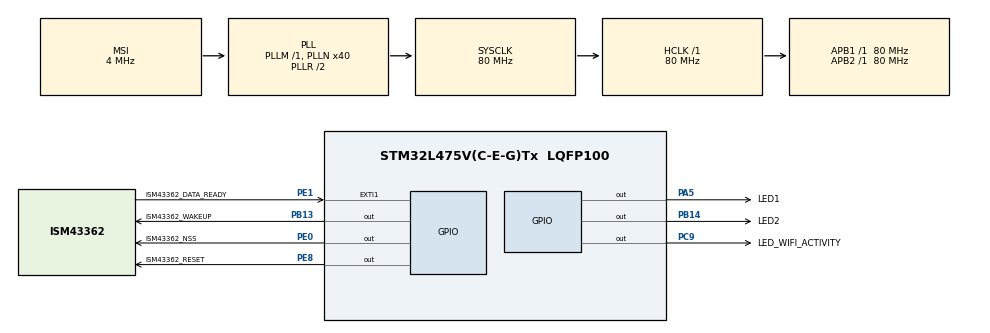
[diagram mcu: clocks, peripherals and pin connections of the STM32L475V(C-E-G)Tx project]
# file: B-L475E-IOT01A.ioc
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Mcu.Family=STM32L4
Mcu.Name=STM32L475V(C-E-G)Tx
Mcu.Package=LQFP100
Mcu.UserConstants=HTS221_I2C,hi2c2
NVIC.EXTI1_IRQn=true\:0\:0\:false\:false\:true\:true\:true
NVIC.PriorityGroup=NVIC_PRIORITYGROUP_4
PA5.GPIO_Label=LED1
PA5.Signal=GPIO_Output
PB13.GPIO_Label=ISM43362_WAKEUP
PB13.Signal=GPIO_Output
PB14.GPIO_Label=LED2
PB14.Signal=GPIO_Output
PB6.Signal=USART1_TX
PB7.Signal=USART1_RX
PC9.GPIO_Label=LED_WIFI_ACTIVITY
PC9.Signal=GPIO_Output
PE0.GPIO_Label=ISM43362_NSS
PE0.PinState=GPIO_PIN_SET
PE0.Signal=GPIO_Output
PE1.GPIO_Label=ISM43362_DATA_READY
PE1.Signal=GPXTI1
PE8.GPIO_Label=ISM43362_RESET
PE8.PinState=GPIO_PIN_SET
PE8.Signal=GPIO_Output
ProjectManager.HeapSize=0x200
ProjectManager.StackSize=0x400
ProjectManager.TargetToolchain=EWARM V8.32
RCC.ADCFreq_Value=48000000
RCC.AHBFreq_Value=80000000
RCC.APB1Freq_Value=80000000
RCC.APB1TimFreq_Value=80000000
RCC.APB2Freq_Value=80000000
RCC.APB2TimFreq_Value=80000000
RCC.CortexFreq_Value=80000000
RCC.HCLKFreq_Value=80000000
RCC.HSE_VALUE=8000000
RCC.HSI_VALUE=16000000
RCC.LSE_VALUE=32768
RCC.MSI_VALUE=4000000
RCC.PLLN=40
RCC.PLLSAI1N=24
RCC.SYSCLKFreq_VALUE=80000000
RCC.SYSCLKSource=RCC_SYSCLKSOURCE_PLLCLK
RCC.USBFreq_Value=48000000
RCC.VCOOutputFreq_Value=160000000
STMicroelectronics.X-CUBE-COMPONENTS.1.4.1.ComponentsCcLEDJjLED=GPIO
STMicroelectronics.X-CUBE-COMPONENTS.1.4.1.HTS221_I2C_HANDLER=HTS221_I2C
VP_STMicroelectronics.X-CUBE-COMPONENTS_VS_LEDJjComponents_1.0.0_1.4.1.Mode=LEDJjComponents
board=custom

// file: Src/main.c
/* USER CODE BEGIN Header */
/**
  ******************************************************************************
  * @file           : main.c
  * @brief          : Main program body
  ******************************************************************************
  * @attention
  *
  * <h2><center>&copy; Copyright (c) 2021 STMicroelectronics.
  * All rights reserved.</center></h2>
  *
  * This software component is licensed by ST under Ultimate Liberty license
  * SLA0044, the "License"; You may not use this file except in compliance with
  * the License. You may obtain a copy of the License at:
  *                             www.st.com/SLA0044
  *
  ******************************************************************************
  */
/* USER CODE END Header */
#include "main.h"

/* USER CODE BEGIN Includes */
#include "led.h"
/* USER CODE END Includes */

void SystemClock_Config(void);
static void MX_GPIO_Init(void);

int main(void)
{

  /* MCU Configuration--------------------------------------------------------*/

  /* Reset of all peripherals, Initializes the Flash interface and the Systick. */
  HAL_Init();

  /* Configure the system clock */
  SystemClock_Config();

  /* Initialize all configured peripherals */
  MX_GPIO_Init();

  /* Infinite loop */
  /* USER CODE BEGIN WHILE */
  while (1)
  {
    BSP_LED_Toggle(LED1);
    BSP_LED_Toggle(LED2);
    HAL_Delay(100);
    /* USER CODE END WHILE */

  }
}

void SystemClock_Config(void)
{
  RCC_OscInitTypeDef RCC_OscInitStruct = {0};
  RCC_ClkInitTypeDef RCC_ClkInitStruct = {0};

  /** Initializes the RCC Oscillators according to the specified parameters
  * in the RCC_OscInitTypeDef structure.
  */
  RCC_OscInitStruct.OscillatorType = RCC_OSCILLATORTYPE_MSI;
  RCC_OscInitStruct.MSIState = RCC_MSI_ON;
  RCC_OscInitStruct.MSICalibrationValue = 0;
  RCC_OscInitStruct.MSIClockRange = RCC_MSIRANGE_6;
  RCC_OscInitStruct.PLL.PLLState = RCC_PLL_ON;
  RCC_OscInitStruct.PLL.PLLSource = RCC_PLLSOURCE_MSI;
  RCC_OscInitStruct.PLL.PLLM = 1;
  RCC_OscInitStruct.PLL.PLLN = 40;
  RCC_OscInitStruct.PLL.PLLP = RCC_PLLP_DIV7;
  RCC_OscInitStruct.PLL.PLLQ = RCC_PLLQ_DIV2;
  RCC_OscInitStruct.PLL.PLLR = RCC_PLLR_DIV2;
  if (HAL_RCC_OscConfig(&RCC_OscInitStruct) != HAL_OK)
  {
    Error_Handler();
  }
  /** Initializes the CPU, AHB and APB buses clocks
  */
  RCC_ClkInitStruct.ClockType = RCC_CLOCKTYPE_HCLK|RCC_CLOCKTYPE_SYSCLK
                              |RCC_CLOCKTYPE_PCLK1|RCC_CLOCKTYPE_PCLK2;
  RCC_ClkInitStruct.SYSCLKSource = RCC_SYSCLKSOURCE_PLLCLK;
  RCC_ClkInitStruct.AHBCLKDivider = RCC_SYSCLK_DIV1;
  RCC_ClkInitStruct.APB1CLKDivider = RCC_HCLK_DIV1;
  RCC_ClkInitStruct.APB2CLKDivider = RCC_HCLK_DIV1;

  if (HAL_RCC_ClockConfig(&RCC_ClkInitStruct, FLASH_LATENCY_4) != HAL_OK)
  {
    Error_Handler();
  }
  /** Configure the main internal regulator output voltage
  */
  if (HAL_PWREx_ControlVoltageScaling(PWR_REGULATOR_VOLTAGE_SCALE1) != HAL_OK)
  {
    Error_Handler();
  }
}

static void MX_GPIO_Init(void)
{
  GPIO_InitTypeDef GPIO_InitStruct = {0};

  /* GPIO Ports Clock Enable */
  __HAL_RCC_GPIOA_CLK_ENABLE();
  __HAL_RCC_GPIOE_CLK_ENABLE();
  __HAL_RCC_GPIOB_CLK_ENABLE();
  __HAL_RCC_GPIOC_CLK_ENABLE();

  /*Configure GPIO pin Output Level */
  HAL_GPIO_WritePin(LED1_GPIO_Port, LED1_Pin, GPIO_PIN_RESET);

  /*Configure GPIO pin Output Level */
  HAL_GPIO_WritePin(GPIOE, ISM43362_RESET_Pin|ISM43362_NSS_Pin, GPIO_PIN_SET);

  /*Configure GPIO pin Output Level */
  HAL_GPIO_WritePin(GPIOB, ISM43362_WAKEUP_Pin|LED2_Pin, GPIO_PIN_RESET);

  /*Configure GPIO pin Output Level */
  HAL_GPIO_WritePin(LED_WIFI_ACTIVITY_GPIO_Port, LED_WIFI_ACTIVITY_Pin, GPIO_PIN_RESET);

  /*Configure GPIO pin : LED1_Pin */
  GPIO_InitStruct.Pin = LED1_Pin;
  GPIO_InitStruct.Mode = GPIO_MODE_OUTPUT_PP;
  GPIO_InitStruct.Pull = GPIO_NOPULL;
  GPIO_InitStruct.Speed = GPIO_SPEED_FREQ_LOW;
  HAL_GPIO_Init(LED1_GPIO_Port, &GPIO_InitStruct);

  /*Configure GPIO pins : ISM43362_RESET_Pin ISM43362_NSS_Pin */
  GPIO_InitStruct.Pin = ISM43362_RESET_Pin|ISM43362_NSS_Pin;
  GPIO_InitStruct.Mode = GPIO_MODE_OUTPUT_PP;
  GPIO_InitStruct.Pull = GPIO_NOPULL;
  GPIO_InitStruct.Speed = GPIO_SPEED_FREQ_LOW;
  HAL_GPIO_Init(GPIOE, &GPIO_InitStruct);

  /*Configure GPIO pins : ISM43362_WAKEUP_Pin LED2_Pin */
  GPIO_InitStruct.Pin = ISM43362_WAKEUP_Pin|LED2_Pin;
  GPIO_InitStruct.Mode = GPIO_MODE_OUTPUT_PP;
  GPIO_InitStruct.Pull = GPIO_NOPULL;
  GPIO_InitStruct.Speed = GPIO_SPEED_FREQ_LOW;
  HAL_GPIO_Init(GPIOB, &GPIO_InitStruct);

  /*Configure GPIO pin : LED_WIFI_ACTIVITY_Pin */
  GPIO_InitStruct.Pin = LED_WIFI_ACTIVITY_Pin;
  GPIO_InitStruct.Mode = GPIO_MODE_OUTPUT_PP;
  GPIO_InitStruct.Pull = GPIO_NOPULL;
  GPIO_InitStruct.Speed = GPIO_SPEED_FREQ_LOW;
  HAL_GPIO_Init(LED_WIFI_ACTIVITY_GPIO_Port, &GPIO_InitStruct);

  /*Configure GPIO pins : PB6 PB7 */
  GPIO_InitStruct.Pin = GPIO_PIN_6|GPIO_PIN_7;
  GPIO_InitStruct.Mode = GPIO_MODE_AF_PP;
  GPIO_InitStruct.Pull = GPIO_NOPULL;
  GPIO_InitStruct.Speed = GPIO_SPEED_FREQ_VERY_HIGH;
  GPIO_InitStruct.Alternate = GPIO_AF7_USART1;
  HAL_GPIO_Init(GPIOB, &GPIO_InitStruct);

  /*Configure GPIO pin : ISM43362_DATA_READY_Pin */
  GPIO_InitStruct.Pin = ISM43362_DATA_READY_Pin;
  GPIO_InitStruct.Mode = GPIO_MODE_IT_RISING;
  GPIO_InitStruct.Pull = GPIO_NOPULL;
  HAL_GPIO_Init(ISM43362_DATA_READY_GPIO_Port, &GPIO_InitStruct);

  /* EXTI interrupt init*/
  HAL_NVIC_SetPriority(EXTI1_IRQn, 0, 0);
  HAL_NVIC_EnableIRQ(EXTI1_IRQn);

}

void Error_Handler(void)
{
  __disable_irq();
  while (1)
  {
  }
}

/************************ (C) COPYRIGHT STMicroelectronics *****END OF FILE****/
